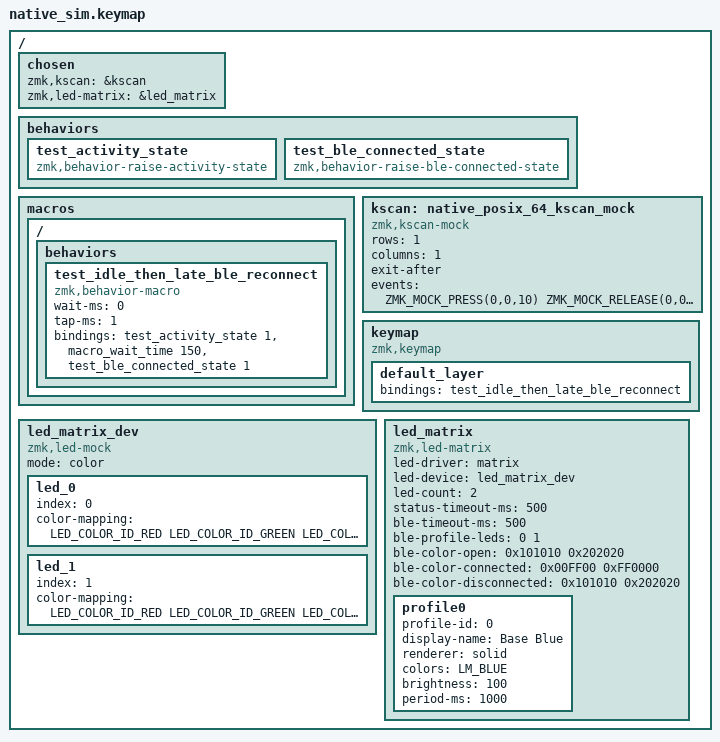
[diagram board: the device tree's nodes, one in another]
#include <dt-bindings/zmk/keys.h>
#include <dt-bindings/zmk/kscan_mock.h>
#include <dt-bindings/zmk/led_matrix.h>
#include <dt-bindings/zmk/led_matrix_colors.h>
#include <dt-bindings/led/led.h>
#include <behaviors.dtsi>

/ {
    chosen {
        zmk,kscan = &kscan;
        zmk,led-matrix = &led_matrix;
    };

    behaviors {
        test_activity_state: test_activity_state {
            compatible = "zmk,behavior-raise-activity-state";
            #binding-cells = <1>;
        };

        test_ble_connected_state: test_ble_connected_state {
            compatible = "zmk,behavior-raise-ble-connected-state";
            #binding-cells = <1>;
        };
    };

    macros {
        ZMK_MACRO(test_idle_then_late_ble_reconnect,
            wait-ms = <0>;
            tap-ms = <1>;
            bindings
                = <&test_activity_state 1>
                , <&macro_wait_time 150>
                , <&test_ble_connected_state 1>
                ;
        )
    };

    kscan: native_posix_64_kscan_mock {
        compatible = "zmk,kscan-mock";
        rows = <1>;
        columns = <1>;
        exit-after;
        events = <
            ZMK_MOCK_PRESS(0,0,10)
            ZMK_MOCK_RELEASE(0,0,400)
        >;
    };

    keymap {
        compatible = "zmk,keymap";

        default_layer {
            bindings = <
                &test_idle_then_late_ble_reconnect
            >;
        };
    };

    led_matrix_dev: led_matrix_dev {
        compatible = "zmk,led-mock";
        mode = "color";

        led_0 {
            index = <0>;
            color-mapping = <LED_COLOR_ID_RED LED_COLOR_ID_GREEN LED_COLOR_ID_BLUE>;
        };

        led_1 {
            index = <1>;
            color-mapping = <LED_COLOR_ID_RED LED_COLOR_ID_GREEN LED_COLOR_ID_BLUE>;
        };
    };

    led_matrix: led_matrix {
        compatible = "zmk,led-matrix";
        led-driver = "matrix";
        led-device = <&led_matrix_dev>;
        led-count = <2>;
        status-timeout-ms = <500>;
        ble-timeout-ms = <500>;
        ble-profile-leds = <0 1>;
        ble-color-open = <0x101010 0x202020>;
        ble-color-connected = <0x00FF00 0xFF0000>;
        ble-color-disconnected = <0x101010 0x202020>;

        profile0 {
            profile-id = <0>;
            display-name = "Base Blue";
            renderer = "solid";
            colors = <LM_BLUE>;
            brightness = <100>;
            period-ms = <1000>;
        };
    };
};
